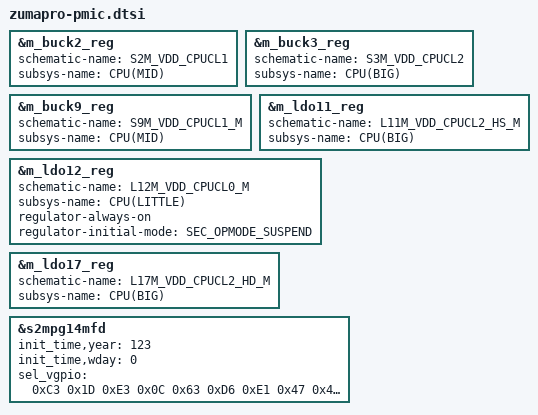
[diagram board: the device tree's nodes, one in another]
// SPDX-License-Identifier: GPL-2.0-only
/*
 * zuma pmic device tree source
 *
 * Copyright 2023 Google LLC.
 *
 */

#include "zuma-pmic.dtsi"

&m_buck2_reg {
	schematic-name = "S2M_VDD_CPUCL1";
	subsys-name = "CPU(MID)";
};

&m_buck3_reg {
	schematic-name = "S3M_VDD_CPUCL2";
	subsys-name = "CPU(BIG)";
};

&m_buck9_reg {
	schematic-name = "S9M_VDD_CPUCL1_M";
	subsys-name = "CPU(MID)";

};

&m_ldo11_reg {
	schematic-name = "L11M_VDD_CPUCL2_HS_M";
	subsys-name = "CPU(BIG)";
};

&m_ldo12_reg {
	schematic-name = "L12M_VDD_CPUCL0_M";
	subsys-name = "CPU(LITTLE)";
	regulator-always-on;
	regulator-initial-mode = <SEC_OPMODE_SUSPEND>;
};

&m_ldo17_reg {
	schematic-name = "L17M_VDD_CPUCL2_HD_M";
	subsys-name = "CPU(BIG)";
};

&s2mpg14mfd {
		init_time,year = <123>;
		init_time,wday = <0>;

		/* PCTRLSEL(VGPIO) 1~11 (CONTROL_SEL#) */
		sel_vgpio = <0xC3 0x1D 0xE3 0x0C 0x63 0xD6
			0xE1 0x47 0x4D 0x96 0x09>;
};

